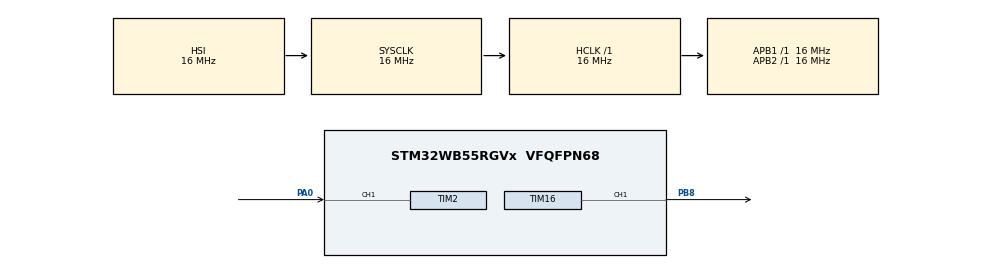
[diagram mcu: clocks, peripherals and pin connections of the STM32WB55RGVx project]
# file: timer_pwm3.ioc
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Mcu.Family=STM32WB
Mcu.Name=STM32WB55RGVx
Mcu.Package=VFQFPN68
NVIC.PriorityGroup=NVIC_PRIORITYGROUP_4
NVIC.TIM2_IRQn=true\:0\:0\:false\:false\:true\:true\:true\:true
OSC_IN.Mode=HSE-External-Oscillator
OSC_IN.Signal=RCC_OSC_IN
OSC_OUT.Mode=HSE-External-Oscillator
OSC_OUT.Signal=RCC_OSC_OUT
PA0.Signal=S_TIM2_CH1
PB8.Signal=S_TIM16_CH1
ProjectManager.HeapSize=0x200
ProjectManager.StackSize=0x400
ProjectManager.TargetToolchain=STM32CubeIDE
RCC.ADCFreq_Value=64000000
RCC.AHB2CLKDivider=RCC_SYSCLK_DIV2
RCC.AHBFreq_Value=16000000
RCC.APB1Freq_Value=16000000
RCC.APB1TimFreq_Value=16000000
RCC.APB2Freq_Value=16000000
RCC.APB2TimFreq_Value=16000000
RCC.APB3Freq_Value=16000000
RCC.Cortex2_Div=SYSTICK_CLKSOURCE_HCLK_DIV8
RCC.CortexFreq_Value=16000000
RCC.HCLKFreq_Value=16000000
RCC.HSE_VALUE=32000000
RCC.HSI48_VALUE=48000000
RCC.HSI_VALUE=16000000
RCC.LSE_VALUE=32768
RCC.PLLSourceVirtual=RCC_PLLSOURCE_HSI
RCC.SMPSCLockSelection=RCC_SMPSCLKSOURCE_HSI
RCC.SMPSCLockSelectionVirtual=RCC_SMPSCLKSOURCE_HSI
RCC.SMPSCLockSelectionVirtualVirtual=RCC_SMPSCLKSOURCE_HSI
RCC.SMPSDivider=1
RCC.SYSCLKFreq_VALUE=16000000
RCC.SYSCLKSource=RCC_SYSCLKSOURCE_HSI
RCC.USBFreq_Value=64000000
RCC.VCOOutputFreq_Value=128000000
SH.S_TIM16_CH1.0=TIM16_CH1,PWM Generation1 CH1
SH.S_TIM2_CH1.0=TIM2_CH1,PWM_Input_1
TIM16.Channel=TIM_CHANNEL_1
TIM16.Period=799
TIM16.Pulse=32768
TIM2.Period=4294967295
TIM2.Prescaler=0
VP_MEMORYMAP_VS_MEMORYMAP.Mode=CurAppReg
VP_TIM16_VS_ClockSourceINT.Mode=Enable_Timer
VP_TIM2_VS_ClockSourceINT.Mode=Internal
board=P-NUCLEO-WB55-NUCLEO

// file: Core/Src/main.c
/* USER CODE BEGIN Header */
/**
  ******************************************************************************
  * @file           : main.c
  * @brief          : Main program body
  ******************************************************************************
  * @attention
  *
  * Copyright (c) 2025 STMicroelectronics.
  * All rights reserved.
  *
  * This software is licensed under terms that can be found in the LICENSE file
  * in the root directory of this software component.
  * If no LICENSE file comes with this software, it is provided AS-IS.
  *
  ******************************************************************************
  */
/* USER CODE END Header */
#include "main.h"

TIM_HandleTypeDef htim2;
TIM_HandleTypeDef htim16;

void SystemClock_Config(void);
void PeriphCommonClock_Config(void);
static void MX_GPIO_Init(void);
static void MX_TIM2_Init(void);
static void MX_TIM16_Init(void);

/* USER CODE BEGIN 0 */
uint32_t ICValue =0;
uint32_t Frequency = 0;
float Duty = 0;

void HAL_TIM_IC_CaptureCallback(TIM_HandleTypeDef *htim)
{
if (htim->Channel == HAL_TIM_ACTIVE_CHANNEL_1)  // If the interrupt is triggered by channel 1
{
// Read the IC value
ICValue = HAL_TIM_ReadCapturedValue(htim, TIM_CHANNEL_1);
if (ICValue != 0)
{
// calculate the Duty Cycle
Duty = (HAL_TIM_ReadCapturedValue(htim, TIM_CHANNEL_2) *100)/ICValue;
Frequency = 16000000/ICValue;
}
}
}

/* USER CODE END 0 */

int main(void)
{

  /* MCU Configuration--------------------------------------------------------*/

  /* Reset of all peripherals, Initializes the Flash interface and the Systick. */
  HAL_Init();

  /* Configure the system clock */
  SystemClock_Config();

  /* Configure the peripherals common clocks */
  PeriphCommonClock_Config();

  /* Initialize all configured peripherals */
  MX_GPIO_Init();
  MX_TIM2_Init();
  MX_TIM16_Init();

  /* Infinite loop */
  /* USER CODE BEGIN WHILE */
  HAL_TIM_IC_Start_IT(&htim2, TIM_CHANNEL_1);   // main channel
  HAL_TIM_IC_Start(&htim2, TIM_CHANNEL_2);   // indirect channel
  HAL_TIM_PWM_Start(&htim16, TIM_CHANNEL_1);
  TIM16->CCR1 = 264;
  while (1)
  {
    /* USER CODE END WHILE */

  }
}

void SystemClock_Config(void)
{
  RCC_OscInitTypeDef RCC_OscInitStruct = {0};
  RCC_ClkInitTypeDef RCC_ClkInitStruct = {0};

  /** Configure the main internal regulator output voltage
  */
  __HAL_PWR_VOLTAGESCALING_CONFIG(PWR_REGULATOR_VOLTAGE_SCALE1);

  /** Initializes the RCC Oscillators according to the specified parameters
  * in the RCC_OscInitTypeDef structure.
  */
  RCC_OscInitStruct.OscillatorType = RCC_OSCILLATORTYPE_HSI|RCC_OSCILLATORTYPE_HSE;
  RCC_OscInitStruct.HSEState = RCC_HSE_ON;
  RCC_OscInitStruct.HSIState = RCC_HSI_ON;
  RCC_OscInitStruct.HSICalibrationValue = RCC_HSICALIBRATION_DEFAULT;
  RCC_OscInitStruct.PLL.PLLState = RCC_PLL_NONE;
  if (HAL_RCC_OscConfig(&RCC_OscInitStruct) != HAL_OK)
  {
    Error_Handler();
  }

  /** Configure the SYSCLKSource, HCLK, PCLK1 and PCLK2 clocks dividers
  */
  RCC_ClkInitStruct.ClockType = RCC_CLOCKTYPE_HCLK4|RCC_CLOCKTYPE_HCLK2
                              |RCC_CLOCKTYPE_HCLK|RCC_CLOCKTYPE_SYSCLK
                              |RCC_CLOCKTYPE_PCLK1|RCC_CLOCKTYPE_PCLK2;
  RCC_ClkInitStruct.SYSCLKSource = RCC_SYSCLKSOURCE_HSI;
  RCC_ClkInitStruct.AHBCLKDivider = RCC_SYSCLK_DIV1;
  RCC_ClkInitStruct.APB1CLKDivider = RCC_HCLK_DIV1;
  RCC_ClkInitStruct.APB2CLKDivider = RCC_HCLK_DIV1;
  RCC_ClkInitStruct.AHBCLK2Divider = RCC_SYSCLK_DIV2;
  RCC_ClkInitStruct.AHBCLK4Divider = RCC_SYSCLK_DIV1;

  if (HAL_RCC_ClockConfig(&RCC_ClkInitStruct, FLASH_LATENCY_0) != HAL_OK)
  {
    Error_Handler();
  }
}

void PeriphCommonClock_Config(void)
{
  RCC_PeriphCLKInitTypeDef PeriphClkInitStruct = {0};

  /** Initializes the peripherals clock
  */
  PeriphClkInitStruct.PeriphClockSelection = RCC_PERIPHCLK_SMPS;
  PeriphClkInitStruct.SmpsClockSelection = RCC_SMPSCLKSOURCE_HSI;
  PeriphClkInitStruct.SmpsDivSelection = RCC_SMPSCLKDIV_RANGE0;

  if (HAL_RCCEx_PeriphCLKConfig(&PeriphClkInitStruct) != HAL_OK)
  {
    Error_Handler();
  }
}

static void MX_TIM2_Init(void)
{

  TIM_ClockConfigTypeDef sClockSourceConfig = {0};
  TIM_SlaveConfigTypeDef sSlaveConfig = {0};
  TIM_IC_InitTypeDef sConfigIC = {0};
  TIM_MasterConfigTypeDef sMasterConfig = {0};

  htim2.Instance = TIM2;
  htim2.Init.Prescaler = 0;
  htim2.Init.CounterMode = TIM_COUNTERMODE_UP;
  htim2.Init.Period = 4294967295;
  htim2.Init.ClockDivision = TIM_CLOCKDIVISION_DIV1;
  htim2.Init.AutoReloadPreload = TIM_AUTORELOAD_PRELOAD_DISABLE;
  if (HAL_TIM_Base_Init(&htim2) != HAL_OK)
  {
    Error_Handler();
  }
  sClockSourceConfig.ClockSource = TIM_CLOCKSOURCE_INTERNAL;
  if (HAL_TIM_ConfigClockSource(&htim2, &sClockSourceConfig) != HAL_OK)
  {
    Error_Handler();
  }
  if (HAL_TIM_IC_Init(&htim2) != HAL_OK)
  {
    Error_Handler();
  }
  sSlaveConfig.SlaveMode = TIM_SLAVEMODE_RESET;
  sSlaveConfig.InputTrigger = TIM_TS_TI1FP1;
  sSlaveConfig.TriggerPolarity = TIM_INPUTCHANNELPOLARITY_RISING;
  sSlaveConfig.TriggerPrescaler = TIM_ICPSC_DIV1;
  sSlaveConfig.TriggerFilter = 0;
  if (HAL_TIM_SlaveConfigSynchro(&htim2, &sSlaveConfig) != HAL_OK)
  {
    Error_Handler();
  }
  sConfigIC.ICPolarity = TIM_INPUTCHANNELPOLARITY_RISING;
  sConfigIC.ICSelection = TIM_ICSELECTION_DIRECTTI;
  sConfigIC.ICPrescaler = TIM_ICPSC_DIV1;
  sConfigIC.ICFilter = 0;
  if (HAL_TIM_IC_ConfigChannel(&htim2, &sConfigIC, TIM_CHANNEL_1) != HAL_OK)
  {
    Error_Handler();
  }
  sConfigIC.ICPolarity = TIM_INPUTCHANNELPOLARITY_FALLING;
  sConfigIC.ICSelection = TIM_ICSELECTION_INDIRECTTI;
  if (HAL_TIM_IC_ConfigChannel(&htim2, &sConfigIC, TIM_CHANNEL_2) != HAL_OK)
  {
    Error_Handler();
  }
  sMasterConfig.MasterOutputTrigger = TIM_TRGO_RESET;
  sMasterConfig.MasterSlaveMode = TIM_MASTERSLAVEMODE_DISABLE;
  if (HAL_TIMEx_MasterConfigSynchronization(&htim2, &sMasterConfig) != HAL_OK)
  {
    Error_Handler();
  }

}

static void MX_TIM16_Init(void)
{

  TIM_OC_InitTypeDef sConfigOC = {0};
  TIM_BreakDeadTimeConfigTypeDef sBreakDeadTimeConfig = {0};

  htim16.Instance = TIM16;
  htim16.Init.Prescaler = 0;
  htim16.Init.CounterMode = TIM_COUNTERMODE_UP;
  htim16.Init.Period = 799;
  htim16.Init.ClockDivision = TIM_CLOCKDIVISION_DIV1;
  htim16.Init.RepetitionCounter = 0;
  htim16.Init.AutoReloadPreload = TIM_AUTORELOAD_PRELOAD_DISABLE;
  if (HAL_TIM_Base_Init(&htim16) != HAL_OK)
  {
    Error_Handler();
  }
  if (HAL_TIM_PWM_Init(&htim16) != HAL_OK)
  {
    Error_Handler();
  }
  sConfigOC.OCMode = TIM_OCMODE_PWM1;
  sConfigOC.Pulse = 32768;
  sConfigOC.OCPolarity = TIM_OCPOLARITY_HIGH;
  sConfigOC.OCNPolarity = TIM_OCNPOLARITY_HIGH;
  sConfigOC.OCFastMode = TIM_OCFAST_DISABLE;
  sConfigOC.OCIdleState = TIM_OCIDLESTATE_RESET;
  sConfigOC.OCNIdleState = TIM_OCNIDLESTATE_RESET;
  if (HAL_TIM_PWM_ConfigChannel(&htim16, &sConfigOC, TIM_CHANNEL_1) != HAL_OK)
  {
    Error_Handler();
  }
  sBreakDeadTimeConfig.OffStateRunMode = TIM_OSSR_DISABLE;
  sBreakDeadTimeConfig.OffStateIDLEMode = TIM_OSSI_DISABLE;
  sBreakDeadTimeConfig.LockLevel = TIM_LOCKLEVEL_OFF;
  sBreakDeadTimeConfig.DeadTime = 0;
  sBreakDeadTimeConfig.BreakState = TIM_BREAK_DISABLE;
  sBreakDeadTimeConfig.BreakPolarity = TIM_BREAKPOLARITY_HIGH;
  sBreakDeadTimeConfig.BreakFilter = 0;
  sBreakDeadTimeConfig.AutomaticOutput = TIM_AUTOMATICOUTPUT_DISABLE;
  if (HAL_TIMEx_ConfigBreakDeadTime(&htim16, &sBreakDeadTimeConfig) != HAL_OK)
  {
    Error_Handler();
  }
  HAL_TIM_MspPostInit(&htim16);

}

static void MX_GPIO_Init(void)
{

  /* GPIO Ports Clock Enable */
  __HAL_RCC_GPIOB_CLK_ENABLE();
  __HAL_RCC_GPIOA_CLK_ENABLE();

}

void Error_Handler(void)
{
  __disable_irq();
  while (1)
  {
  }
}
